AUTOSAR XML (schema 4-2-2)
package /IoHwAb
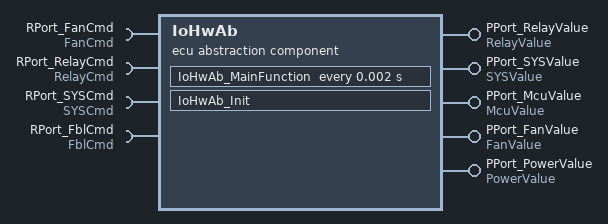
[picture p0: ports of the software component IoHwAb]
  ecu abstraction sw component type IoHwAb
    4 x provide port:
      PPort_RelayValue: provided-interface=RelayValue
      PPort_SYSValue: provided-interface=SYSValue
      PPort_McuValue: provided-interface=McuValue
      PPort_FanValue: provided-interface=FanValue
    4 x require port:
      RPort_FanCmd: required-interface=FanCmd
      RPort_RelayCmd: required-interface=RelayCmd
      RPort_SYSCmd: required-interface=SYSCmd
      RPort_FblCmd: required-interface=FblCmd
    provide port PPort_PowerValue: provided-interface=PowerValue
    behavior SwcInternalBehavior
      timing event TE_IoHwAb_MainFunction_2ms: start-on-event=IoHwAb_MainFunction, period=0.002
      runnable IoHwAb_Init
      runnable IoHwAb_MainFunction
        data-receive-point-by-arguments:
          6 x access:
            DRPA_OutFanPWMFrq_Hz_0: accessed-variable=RPort_FanCmd.OutFanPWMFrq_Hz
            DRPA_OutFanDuty_pct_0: accessed-variable=RPort_FanCmd.OutFanDuty_pct
            DRPA_RadyToSleep_flg_0: accessed-variable=RPort_SYSCmd.RadyToSleep_flg
            DRPA_GlobalHCtrCmd_flg_0: accessed-variable=RPort_RelayCmd.GlobalHCtrCmd_flg
            DRPA_PosCtrCmd_flg_0: accessed-variable=RPort_RelayCmd.PosCtrCmd_flg
            DRPA_FBLForbid_flg_0: accessed-variable=RPort_FblCmd.FBLForbid_flg
        data-send-points:
          7 x access:
            DSP_FeedbackVolt_V_0: accessed-variable=PPort_FanValue.FeedbackVolt_V
            DSP_BSWRequestReset_flg_0: accessed-variable=PPort_SYSValue.BSWRequestReset_flg
            DSP_GlobalHCtrState_flg_0: accessed-variable=PPort_RelayValue.GlobalHCtrState_flg
            DSP_PosCtrCmdState_flg_0: accessed-variable=PPort_RelayValue.PosCtrCmdState_flg
            DSP_BSWInitFinish_flg_0: accessed-variable=PPort_McuValue.BSWInitFinish_flg
            DSP_KL30Volt_V_0: accessed-variable=PPort_PowerValue.KL30Volt_V
            DSP_KL30VoltVld_flg_0: accessed-variable=PPort_PowerValue.KL30VoltVld_flg
